# UPD70F3508 register map
Vendor: Renesas; Series: V850E2/Px4; File version: 1.0
CPU: other r0p0, little endian, no MPU, FPU, 4 interrupt priority bits
Registers are 8-bit, read-write, reset 0x0 unless marked. A register's access mark holds for its fields unless they carry their own. Offsets are from the block's base; [hi:lo] are bit positions.

## TAPA1_CTL — Timer Option Module 1 Control Registers (base0 region)
Base 0xFF816020
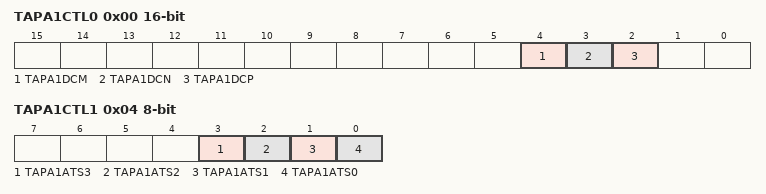
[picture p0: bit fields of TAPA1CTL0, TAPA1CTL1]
0x00 TAPA1CTL0 16-bit — TAPA1 Control Register 0 - Hi-Z edge/mode control
  [4] TAPA1DCM — Clearing condition specification bit
  [3] TAPA1DCN — Hi-Z input edge selection bit N (falling)
  [2] TAPA1DCP — Hi-Z input edge selection bit P (rising)
0x04 TAPA1CTL1 — TAPA1 Control Register 1 - A/D converter trigger select (n=0,1 only)
  [3] TAPA1ATS3 — A/D converter trigger 1 select bit 1
  [2] TAPA1ATS2 — A/D converter trigger 1 select bit 0
  [1] TAPA1ATS1 — A/D converter trigger 0 select bit 1
  [0] TAPA1ATS0 — A/D converter trigger 0 select bit 0

## TAPA2_CTL — Timer Option Module 2 Control Registers (base0 region; no CTL1)
Base 0xFF817020
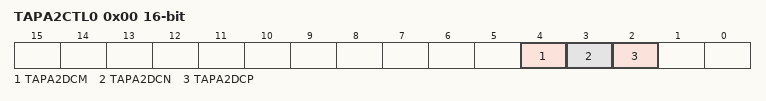
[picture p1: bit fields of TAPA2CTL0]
0x00 TAPA2CTL0 16-bit — TAPA2 Control Register 0 - Hi-Z edge/mode control
  [4] TAPA2DCM — Clearing condition specification bit
  [3] TAPA2DCN — Hi-Z input edge selection bit N (falling)
  [2] TAPA2DCP — Hi-Z input edge selection bit P (rising)

## TAPA3_CTL — Timer Option Module 3 Control Registers (base0 region; no CTL1)
Base 0xFF818020
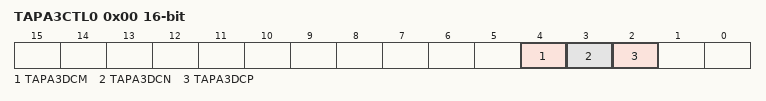
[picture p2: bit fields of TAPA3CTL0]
0x00 TAPA3CTL0 16-bit — TAPA3 Control Register 0 - Hi-Z edge/mode control
  [4] TAPA3DCM — Clearing condition specification bit
  [3] TAPA3DCN — Hi-Z input edge selection bit N (falling)
  [2] TAPA3DCP — Hi-Z input edge selection bit P (rising)

## ENCA0_CTL — Encoder Timer 0 — control register bank (base0+0x40 = 0xFF819040)
Base 0xFF819040
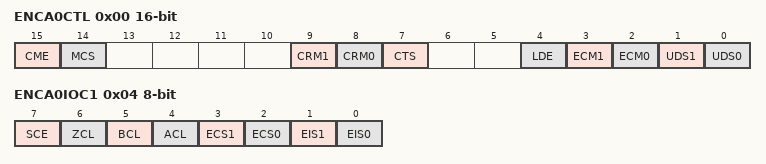
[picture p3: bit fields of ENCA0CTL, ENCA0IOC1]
0x00 ENCA0CTL 16-bit — ENCA0 Control Register — 16-bit, write prohibited during operation
  [15] CME — Compare-match interrupt mask enable: 0=disable masking, 1=enable masking
  [14] MCS — Mask cancel trigger select: 0=write to CCR1, 1=counter clear/underflow load
  [9] CRM1 — CCR1 mode select: 0=comparison register, 1=capture register
  [8] CRM0 — CCR0 mode select: 0=comparison register, 1=capture register
  [7] CTS — CCR1 capture trigger select: 0=ENCAnI1 input, 1=ENCAnEC input (valid when CRM1=1)
  [4] LDE — Underflow load enable: 0=disable CCR0 load on underflow, 1=enable (valid when CRM0=0)
  [3] ECM1 — CCR1 compare-match clear: 0=no clear, 1=clear counter to 0000H if next count down
  [2] ECM0 — CCR0 compare-match clear: 0=no clear, 1=clear counter to 0000H if next count up
  [1] UDS1 — Up/down control bit 1
  [0] UDS0 — Up/down control bit 0
0x04 ENCA0IOC1 — ENCA0 I/O Control Register 1 — encoder/clearing edge and level selection, write prohibited during operation
  [7] SCE — Clear method select: 0=edge detection on ENCAnEC, 1=level detection on ENCAnEC/E0/E1
  [6] ZCL — ENCAnEC active clear level: 0=low, 1=high (valid when SCE=1)
  [5] BCL — ENCAnE1 active clear level: 0=low, 1=high (valid when SCE=1)
  [4] ACL — ENCAnE0 active clear level: 0=low, 1=high (valid when SCE=1)
  [3] ECS1 — Encoder-clear input (ENCAnEC) valid edge bit 1 (valid when SCE=0)
  [2] ECS0 — Encoder-clear input (ENCAnEC) valid edge bit 0 (valid when SCE=0)
  [1] EIS1 — Encoder input (ENCAnE0/E1) valid edge bit 1 (valid when UDS[1:0]=00B or 01B)
  [0] EIS0 — Encoder input (ENCAnE0/E1) valid edge bit 0 (valid when UDS[1:0]=00B or 01B)

## ENCA1_CTL — Encoder Timer 1 — control register bank (base0+0x40 = 0xFF81A040)
Base 0xFF81A040
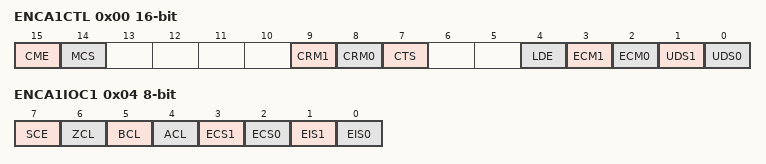
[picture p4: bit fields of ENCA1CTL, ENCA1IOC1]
0x00 ENCA1CTL 16-bit — ENCA1 Control Register — 16-bit, write prohibited during operation
  [15] CME — Compare-match interrupt mask enable: 0=disable masking, 1=enable masking
  [14] MCS — Mask cancel trigger select: 0=write to CCR1, 1=counter clear/underflow load
  [9] CRM1 — CCR1 mode select: 0=comparison register, 1=capture register
  [8] CRM0 — CCR0 mode select: 0=comparison register, 1=capture register
  [7] CTS — CCR1 capture trigger select: 0=ENCAnI1 input, 1=ENCAnEC input (valid when CRM1=1)
  [4] LDE — Underflow load enable: 0=disable CCR0 load on underflow, 1=enable (valid when CRM0=0)
  [3] ECM1 — CCR1 compare-match clear: 0=no clear, 1=clear counter to 0000H if next count down
  [2] ECM0 — CCR0 compare-match clear: 0=no clear, 1=clear counter to 0000H if next count up
  [1] UDS1 — Up/down control bit 1
  [0] UDS0 — Up/down control bit 0
0x04 ENCA1IOC1 — ENCA1 I/O Control Register 1 — encoder/clearing edge and level selection, write prohibited during operation
  [7] SCE — Clear method select: 0=edge detection on ENCAnEC, 1=level detection on ENCAnEC/E0/E1
  [6] ZCL — ENCAnEC active clear level: 0=low, 1=high (valid when SCE=1)
  [5] BCL — ENCAnE1 active clear level: 0=low, 1=high (valid when SCE=1)
  [4] ACL — ENCAnE0 active clear level: 0=low, 1=high (valid when SCE=1)
  [3] ECS1 — Encoder-clear input (ENCAnEC) valid edge bit 1 (valid when SCE=0)
  [2] ECS0 — Encoder-clear input (ENCAnEC) valid edge bit 0 (valid when SCE=0)
  [1] EIS1 — Encoder input (ENCAnE0/E1) valid edge bit 1 (valid when UDS[1:0]=00B or 01B)
  [0] EIS0 — Encoder input (ENCAnE0/E1) valid edge bit 0 (valid when UDS[1:0]=00B or 01B)
